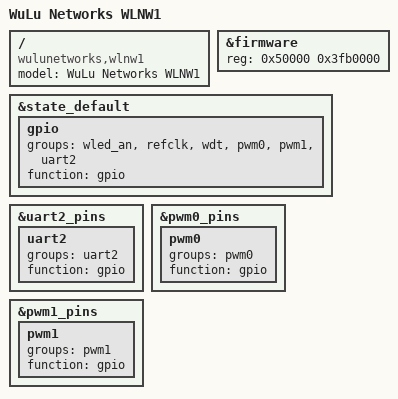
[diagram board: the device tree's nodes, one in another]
#include "mt7628an_morse_ekh03.dtsi"
#include "mt7628an_morse_ekh03_rgbled.dtsi"

/ {
	compatible = "wulunetworks,wlnw1", "mediatek,mt7628an-soc";
	model = "WuLu Networks WLNW1";
};

&firmware {
	reg = <0x50000 0x3fb0000>;
};

&state_default {
	gpio {
		groups = "wled_an", "refclk", "wdt", "pwm0", "pwm1", "uart2";
		function = "gpio";
	};
};

&uart2_pins {
	uart2 {
		groups = "uart2";
		function = "gpio";
	};
};

&pwm0_pins {
	pwm0 {
		groups = "pwm0";
		function = "gpio";
	};
};

&pwm1_pins {
	pwm1 {
		groups = "pwm1";
		function = "gpio";
	};
};
